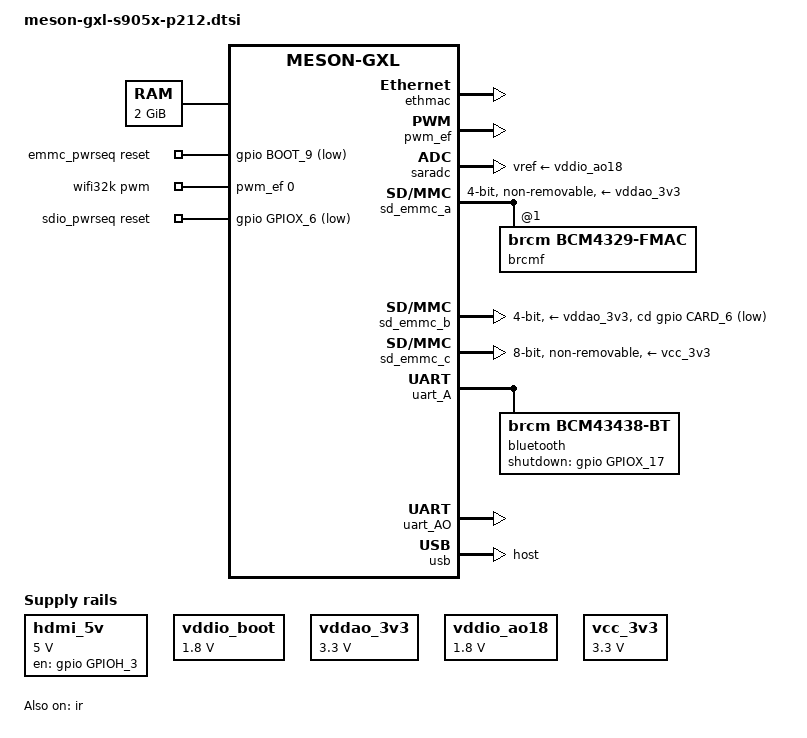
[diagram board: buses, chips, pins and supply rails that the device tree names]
#include "meson-gxl-s905x.dtsi"
/ {
	aliases {
		serial0 = &uart_AO;
		ethernet0 = &ethmac;
	};
	chosen {
		stdout-path = "serial0:115200n8";
	};
	memory@0 {
		device_type = "memory";
		reg = <0x0 0x0 0x0 0x80000000>;
	};
	hdmi_5v: regulator-hdmi-5v {
		compatible = "regulator-fixed";
		regulator-name = "HDMI_5V";
		regulator-min-microvolt = <5000000>;
		regulator-max-microvolt = <5000000>;
		gpio = <&gpio GPIOH_3 GPIO_ACTIVE_HIGH>;
		enable-active-high;
		regulator-always-on;
	};
	vddio_boot: regulator-vddio_boot {
		compatible = "regulator-fixed";
		regulator-name = "VDDIO_BOOT";
		regulator-min-microvolt = <1800000>;
		regulator-max-microvolt = <1800000>;
	};
	vddao_3v3: regulator-vddao_3v3 {
		compatible = "regulator-fixed";
		regulator-name = "VDDAO_3V3";
		regulator-min-microvolt = <3300000>;
		regulator-max-microvolt = <3300000>;
	};
	vddio_ao18: regulator-vddio_ao18 {
		compatible = "regulator-fixed";
		regulator-name = "VDDIO_AO18";
		regulator-min-microvolt = <1800000>;
		regulator-max-microvolt = <1800000>;
	};
	vcc_3v3: regulator-vcc_3v3 {
		compatible = "regulator-fixed";
		regulator-name = "VCC_3V3";
		regulator-min-microvolt = <3300000>;
		regulator-max-microvolt = <3300000>;
	};
	emmc_pwrseq: emmc-pwrseq {
		compatible = "mmc-pwrseq-emmc";
		reset-gpios = <&gpio BOOT_9 GPIO_ACTIVE_LOW>;
	};
	wifi32k: wifi32k {
		compatible = "pwm-clock";
		#clock-cells = <0>;
		clock-frequency = <32768>;
		pwms = <&pwm_ef 0 30518 0>;  
	};
	sdio_pwrseq: sdio-pwrseq {
		compatible = "mmc-pwrseq-simple";
		reset-gpios = <&gpio GPIOX_6 GPIO_ACTIVE_LOW>;
		clocks = <&wifi32k>;
		clock-names = "ext_clock";
	};
};
&ethmac {
	status = "okay";
};
&ir {
	status = "okay";
	pinctrl-0 = <&remote_input_ao_pins>;
	pinctrl-names = "default";
};
&pwm_ef {
	status = "okay";
	pinctrl-0 = <&pwm_e_pins>;
	pinctrl-names = "default";
	clocks = <&clkc CLKID_FCLK_DIV4>;
	clock-names = "clkin0";
};
&saradc {
	status = "okay";
	vref-supply = <&vddio_ao18>;
};
&sd_emmc_a {
	status = "okay";
	pinctrl-0 = <&sdio_pins>;
	pinctrl-1 = <&sdio_clk_gate_pins>;
	pinctrl-names = "default", "clk-gate";
	#address-cells = <1>;
	#size-cells = <0>;
	bus-width = <4>;
	cap-sd-highspeed;
	max-frequency = <50000000>;
	non-removable;
	disable-wp;
	keep-power-in-suspend;
	mmc-pwrseq = <&sdio_pwrseq>;
	vmmc-supply = <&vddao_3v3>;
	vqmmc-supply = <&vddio_boot>;
	brcmf: wifi@1 {
		reg = <1>;
		compatible = "brcm,bcm4329-fmac";
	};
};
&sd_emmc_b {
	status = "okay";
	pinctrl-0 = <&sdcard_pins>;
	pinctrl-1 = <&sdcard_clk_gate_pins>;
	pinctrl-names = "default", "clk-gate";
	bus-width = <4>;
	cap-sd-highspeed;
	max-frequency = <50000000>;
	disable-wp;
	cd-gpios = <&gpio CARD_6 GPIO_ACTIVE_LOW>;
	vmmc-supply = <&vddao_3v3>;
	vqmmc-supply = <&vddio_boot>;
};
&sd_emmc_c {
	status = "okay";
	pinctrl-0 = <&emmc_pins>, <&emmc_ds_pins>;
	pinctrl-1 = <&emmc_clk_gate_pins>;
	pinctrl-names = "default", "clk-gate";
	bus-width = <8>;
	cap-mmc-highspeed;
	max-frequency = <200000000>;
	non-removable;
	disable-wp;
	mmc-ddr-1_8v;
	mmc-hs200-1_8v;
	mmc-pwrseq = <&emmc_pwrseq>;
	vmmc-supply = <&vcc_3v3>;
	vqmmc-supply = <&vddio_boot>;
};
&uart_A {
	status = "okay";
	pinctrl-0 = <&uart_a_pins>, <&uart_a_cts_rts_pins>;
	pinctrl-names = "default";
	uart-has-rtscts;
	bluetooth {
		compatible = "brcm,bcm43438-bt";
		shutdown-gpios = <&gpio GPIOX_17 GPIO_ACTIVE_HIGH>;
		max-speed = <2000000>;
		clocks = <&wifi32k>;
		clock-names = "lpo";
	};
};
&uart_AO {
	status = "okay";
	pinctrl-0 = <&uart_ao_a_pins>;
	pinctrl-names = "default";
};
&usb {
	status = "okay";
	dr_mode = "host";
};
&usb2_phy0 {
	phy-supply = <&hdmi_5v>;
};
